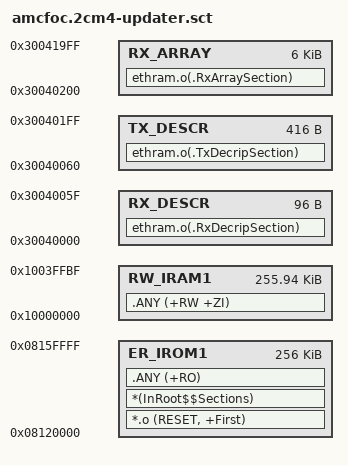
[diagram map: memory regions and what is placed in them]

; this scatter file is for the eloader. it uses:
; - 1M of flash 
; - ram in banks sram1 and sram2  w/ a memory hole of 64 bytes on top for ipc (shall we make make 256?)
; - the placing of the memory required by the ETH driver (commented out because eloader does not compile the driver)

LR_IROM1 0x08120000 0x00040000  {    ; load region size_region
  
  ; flash
  ER_IROM1 0x08120000 0x00040000  {  ; load address = execution address
   *.o (RESET, +First)
   *(InRoot$$Sections)
   .ANY (+RO)
  }
  
  ; eth mapping. comment it out if ethram.o is not linked
  RX_DESCR	0x30040000 0x00000060 {
  	ethram.o(.RxDecripSection)
  }
  TX_DESCR	0x30040060 0x000001A0 {
  	ethram.o(.TxDecripSection)
  }
  RX_ARRAY 	0x30040200 0x00001800 {
  	ethram.o(.RxArraySection)
  }
  
  ; banks sram1 and sram2 joined together w/ a memory hole on top
  RW_IRAM1 0x10000000 0x0003FFC0 {
   .ANY (+RW +ZI)
  }
  

}
